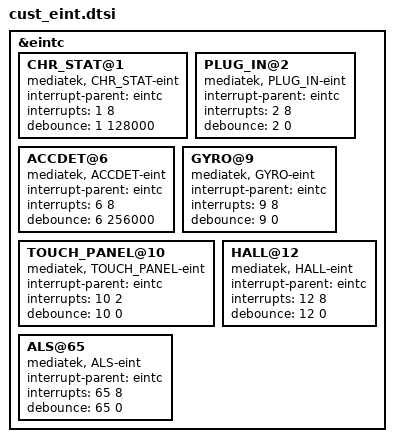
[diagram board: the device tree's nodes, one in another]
/*
 * Generated by MTK SP DrvGen Version 03.13.6 for MT6753. Copyright MediaTek Inc. (C) 2013.
 * Thu Nov 05 22:03:51 2015
 * Do Not Modify the File.
 */

/*************************
 * EINT DTSI File
*************************/

&eintc {
	CHR_STAT@1 {
		compatible = "mediatek, CHR_STAT-eint";
		interrupt-parent = <&eintc>;
		interrupts = <1 8>;
		debounce = <1 128000>;
	};

	PLUG_IN@2 {
		compatible = "mediatek, PLUG_IN-eint";
		interrupt-parent = <&eintc>;
		interrupts = <2 8>;
		debounce = <2 0>;
	};

	ACCDET@6 {
		compatible = "mediatek, ACCDET-eint";
		interrupt-parent = <&eintc>;
		interrupts = <6 8>;
		debounce = <6 256000>;
	};

	GYRO@9 {
		compatible = "mediatek, GYRO-eint";
		interrupt-parent = <&eintc>;
		interrupts = <9 8>;
		debounce = <9 0>;
	};

	TOUCH_PANEL@10 {
		compatible = "mediatek, TOUCH_PANEL-eint";
		interrupt-parent = <&eintc>;
		interrupts = <10 2>;
		debounce = <10 0>;
	};

	HALL@12 {
		compatible = "mediatek, HALL-eint";
		interrupt-parent = <&eintc>;
		interrupts = <12 8>;
		debounce = <12 0>;
	};

	ALS@65 {
		compatible = "mediatek, ALS-eint";
		interrupt-parent = <&eintc>;
		interrupts = <65 8>;
		debounce = <65 0>;
	};

};
